# CS32F030x register map
File version: 1.0
Registers are 32-bit, read-write, reset 0x0 unless marked. A register's access mark holds for its fields unless they carry their own. Offsets are from the block's base; [hi:lo] are bit positions; {n}, {i} and the like mark numbered series.

## RTC — Real-time clock
Base 0x40002800
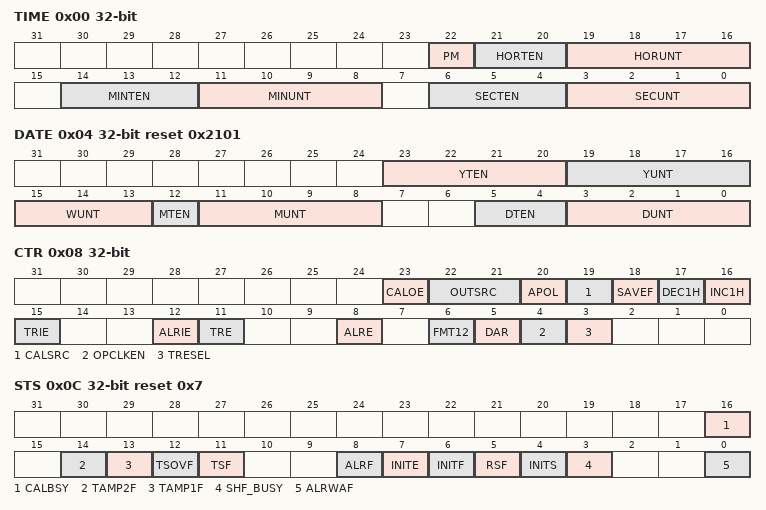
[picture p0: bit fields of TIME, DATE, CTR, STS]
0x00 TIME
  [22] PM — AM/PM notation
  [21:20] HORTEN — Hour tens in BCD format
  [19:16] HORUNT — Hour units in BCD format
  [14:12] MINTEN — Minute tens in BCD format
  [11:8] MINUNT — Minute units in BCD format
  [6:4] SECTEN — Second tens in BCD format
  [3:0] SECUNT — Second units in BCD format
0x04 DATE reset 0x2101
  [23:20] YTEN — Year tens in BCD format
  [19:16] YUNT — Year units in BCD format
  [15:13] WUNT — Week day units
  [12] MTEN — Month tens in BCD format
  [11:8] MUNT — Month units in BCD format
  [5:4] DTEN — Date tens in BCD format
  [3:0] DUNT — Date units in BCD format
0x08 CTR access per field — control register
  [23] CALOE rw — Calibration output enable
  [22:21] OUTSRC rw — Output source
  [20] APOL rw — Alarm Output polarity
  [19] CALSRC rw — Calibration output source
  [18] SAVEF rw — saving time flag
  [17] DEC1H wo — decrease 1 hour
  [16] INC1H wo — increase 1 hour
  [15] TRIE rw — Time recording interrupt enable
  [12] ALRIE rw — Alarm interrupt enable
  [11] TRE rw — Time recording enable
  [8] ALRE rw — Alarm enable
  [6] FMT12 rw — 12/24 format
  [5] DAR rw — direct access registers
  [4] OPCLKEN rw — outside precise clock detection enable
  [3] TRESEL rw — Time recording edge select
0x0C STS access per field reset 0x7 — status register
  [16] CALBSY ro — Calibration busy
  [14] TAMP2F rw — RTC_INBREAK2 detection flag
  [13] TAMP1F rw — RTC_INBREAK1 detection flag
  [12] TSOVF rw — Time-stamp overflow flag
  [11] TSF rw — Time-stamp flag
  [8] ALRF rw — Alarm flag
  [7] INITE rw — Initialization mode enbale
  [6] INITF ro — Initialization mode endter flag
  [5] RSF rw — Registers synchronization flag
  [4] INITS ro — Initialization status flag
  [3] SHF_BUSY rw — Shift busy
  [0] ALRWAF ro — Alarm write access flag
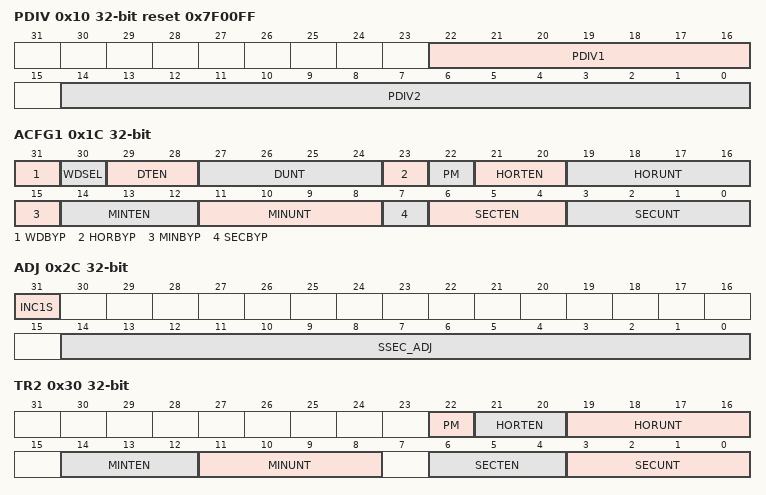
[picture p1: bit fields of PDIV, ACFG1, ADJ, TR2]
0x10 PDIV reset 0x7F00FF — pre-divider register
  [22:16] PDIV1 — first pre-divider factor
  [14:0] PDIV2 — second pre-divider factor
0x1C ACFG1 — alarm config1 register
  [31] WDBYP — week/date bypass
  [30] WDSEL — week/date selection
  [29:28] DTEN — Date tens in BCD format.
  [27:24] DUNT — Date units or day in BCD format.
  [23] HORBYP — hours bypass
  [22] PM — AM/PM notation
  [21:20] HORTEN — Hour tens in BCD format.
  [19:16] HORUNT — Hour units in BCD format.
  [15] MINBYP — minutes bypass
  [14:12] MINTEN — Minute tens in BCD format.
  [11:8] MINUNT — Minute units in BCD format.
  [7] SECBYP — seconds bypass
  [6:4] SECTEN — Second tens in BCD format.
  [3:0] SECUNT — Second units in BCD format.
0x24 CCODE wo — control code register
  [7:0] CCODE — Control code
0x28 SSEC ro — subsecond register
  [15:0] SSEC — subsecond
0x2C ADJ wo — adjustment register
  [31] INC1S — increase one second
  [14:0] SSEC_ADJ — subsecond adjustment
0x30 TR2 ro — recording2 register
  [22] PM — AM/PM notation
  [21:20] HORTEN — Hour tens in BCD format.
  [19:16] HORUNT — Hour units in BCD format.
  [14:12] MINTEN — Minute tens in BCD format.
  [11:8] MINUNT — Minute units in BCD format.
  [6:4] SECTEN — Second tens in BCD format.
  [3:0] SECUNT — Second units in BCD format.
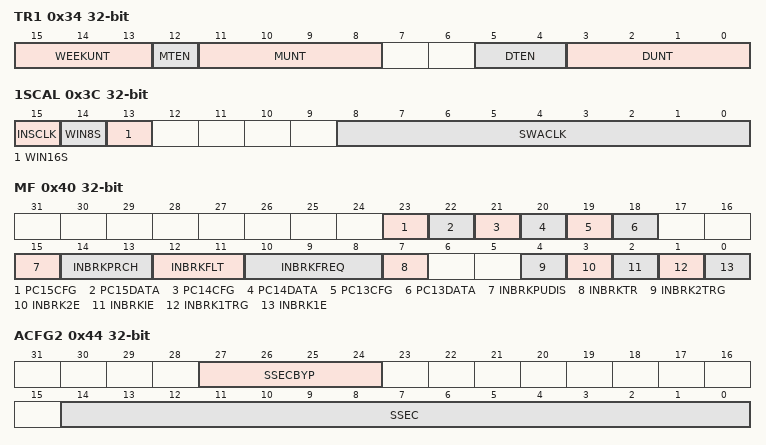
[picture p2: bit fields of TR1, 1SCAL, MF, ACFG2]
0x34 TR1 ro — recording1 register
  [15:13] WEEKUNT — Week units
  [12] MTEN — Month tens in BCD format
  [11:8] MUNT — Month units in BCD format
  [5:4] DTEN — Date tens in BCD format
  [3:0] DUNT — Date units in BCD format
0x38 TR3 ro — recording3 register
  [15:0] SSEC — Subsecond
0x3C 1SCAL — 1Hz clock calibration register
  [15] INSCLK — Insert RTC clock
  [14] WIN8S — 8-second calibration window
  [13] WIN16S — 16-second calibration window
  [8:0] SWACLK — swallow RTC clock
0x40 MF — multiplex function register
  [23] PC15CFG — PC15 config
  [22] PC15DATA — PC15 output data
  [21] PC14CFG — PC14 config
  [20] PC14DATA — PC14 output data
  [19] PC13CFG — PC13 config
  [18] PC13DATA — RTC_ALARM output type/PC13 output data
  [15] INBRKPUDIS — RTC_INBREAKx pull-up disable
  [14:13] INBRKPRCH — RTC_INBREAKx precharge duration
  [12:11] INBRKFLT — RTC_INBREAKx filter count
  [10:8] INBRKFREQ — Inbreak sampling frequency
  [7] INBRKTR — Activate timestamp on inbreak detection event
  [4] INBRK2TRG — Active level for RTC_INBREAK2 input
  [3] INBRK2E — RTC_INBREAK2 input detection enable
  [2] INBRKIE — Inbreak interrupt enable
  [1] INBRK1TRG — Active level for RTC_INBREAK1 input
  [0] INBRK1E — Active level for RTC_INBREAK1 input
0x44 ACFG2 — alarm config2 register
  [27:24] SSECBYP — Subsecond bypass
  [14:0] SSEC — Subsecond
0x50 AO0 — always on registers 0
  [31:0] AO
{0x50+4i} AO{i} (i=1..4) — RTC always on registers {i}
  [31:0] AO
